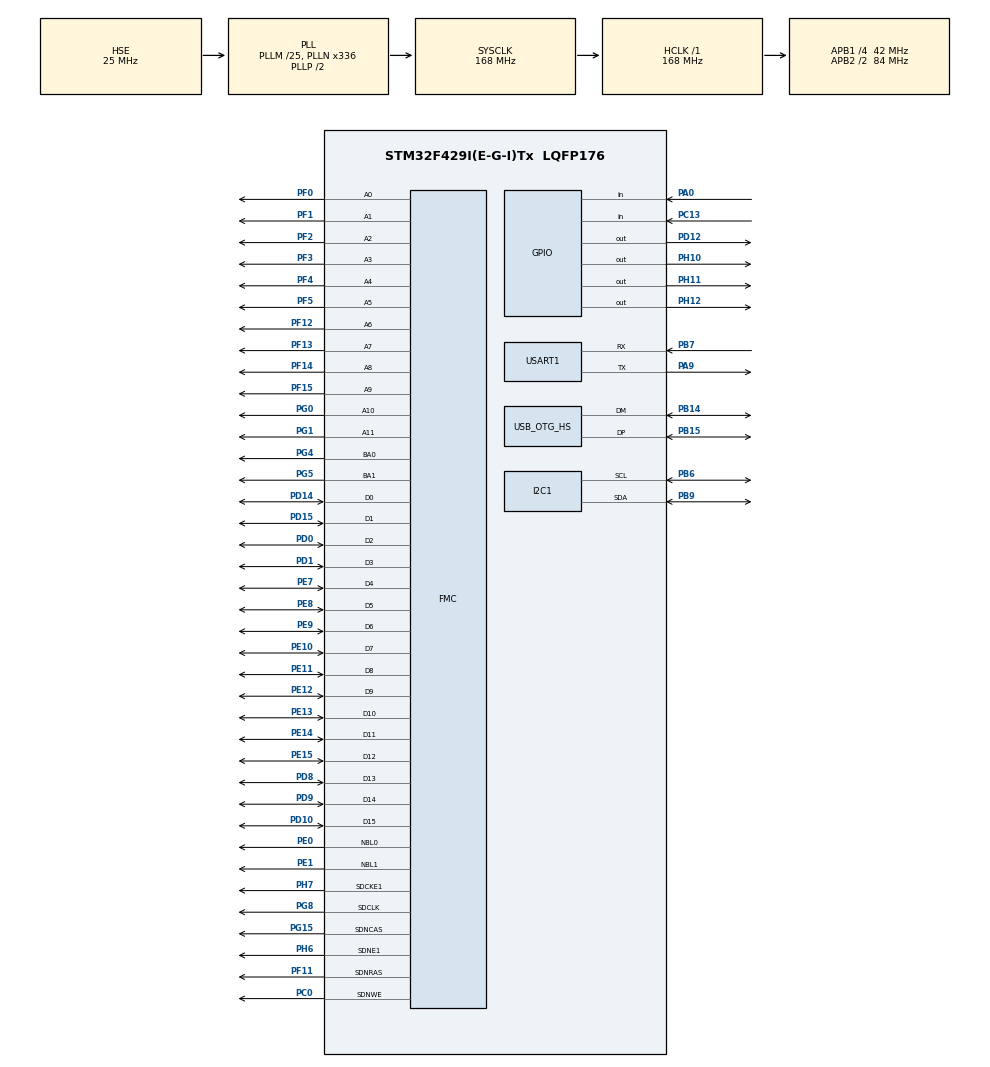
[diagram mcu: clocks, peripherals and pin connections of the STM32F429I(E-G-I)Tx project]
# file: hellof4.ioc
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Dma.I2C1_RX.1.Direction=DMA_PERIPH_TO_MEMORY
Dma.I2C1_RX.1.FIFOMode=DMA_FIFOMODE_DISABLE
Dma.I2C1_RX.1.Instance=DMA1_Stream0
Dma.I2C1_RX.1.MemDataAlignment=DMA_MDATAALIGN_BYTE
Dma.I2C1_RX.1.MemInc=DMA_MINC_ENABLE
Dma.I2C1_RX.1.Mode=DMA_NORMAL
Dma.I2C1_RX.1.PeriphDataAlignment=DMA_PDATAALIGN_BYTE
Dma.I2C1_RX.1.PeriphInc=DMA_PINC_DISABLE
Dma.I2C1_RX.1.Priority=DMA_PRIORITY_HIGH
Dma.I2C1_TX.2.Direction=DMA_MEMORY_TO_PERIPH
Dma.I2C1_TX.2.FIFOMode=DMA_FIFOMODE_DISABLE
Dma.I2C1_TX.2.Instance=DMA1_Stream6
Dma.I2C1_TX.2.MemDataAlignment=DMA_MDATAALIGN_BYTE
Dma.I2C1_TX.2.MemInc=DMA_MINC_ENABLE
Dma.I2C1_TX.2.Mode=DMA_NORMAL
Dma.I2C1_TX.2.PeriphDataAlignment=DMA_PDATAALIGN_BYTE
Dma.I2C1_TX.2.PeriphInc=DMA_PINC_DISABLE
Dma.I2C1_TX.2.Priority=DMA_PRIORITY_HIGH
Dma.Request0=USART1_TX
Dma.Request1=I2C1_RX
Dma.Request2=I2C1_TX
Dma.USART1_TX.0.Direction=DMA_MEMORY_TO_PERIPH
Dma.USART1_TX.0.FIFOMode=DMA_FIFOMODE_DISABLE
Dma.USART1_TX.0.Instance=DMA2_Stream7
Dma.USART1_TX.0.MemDataAlignment=DMA_MDATAALIGN_BYTE
Dma.USART1_TX.0.MemInc=DMA_MINC_ENABLE
Dma.USART1_TX.0.Mode=DMA_NORMAL
Dma.USART1_TX.0.PeriphDataAlignment=DMA_PDATAALIGN_BYTE
Dma.USART1_TX.0.PeriphInc=DMA_PINC_DISABLE
Dma.USART1_TX.0.Priority=DMA_PRIORITY_HIGH
FATFS._CODE_PAGE=936
FATFS._USE_LFN=1
FMC.CASLatency1=FMC_SDRAM_CAS_LATENCY_2
FMC.ExitSelfRefreshDelay1=7
FMC.LoadToActiveDelay1=2
FMC.RCDDelay1=2
FMC.RPDelay1=2
FMC.ReadBurst1=FMC_SDRAM_RBURST_ENABLE
FMC.RowCycleDelay1=7
FMC.SDClockPeriod1=FMC_SDRAM_CLOCK_PERIOD_2
FMC.SelfRefreshTime1=4
FMC.WriteRecoveryTime1=3
Mcu.Family=STM32F4
Mcu.Name=STM32F429I(E-G-I)Tx
Mcu.Package=LQFP176
NVIC.DMA1_Stream0_IRQn=true\:0\:0\:false\:false\:true
NVIC.DMA1_Stream6_IRQn=true\:0\:0\:false\:false\:true
NVIC.DMA2_Stream7_IRQn=true\:0\:0\:false\:false\:true
NVIC.OTG_HS_IRQn=true\:0\:0\:false\:false\:true
NVIC.PriorityGroup=NVIC_PRIORITYGROUP_4
PA0/WKUP.Signal=GPIO_Input
PA13.Mode=Serial_Wire
PA13.Signal=SYS_JTMS-SWDIO
PA14.Mode=Serial_Wire
PA14.Signal=SYS_JTCK-SWCLK
PA9.Mode=Asynchronous
PA9.Signal=USART1_TX
PB14.Mode=Host_FS
PB14.Signal=USB_OTG_HS_DM
PB15.Mode=Host_FS
PB15.Signal=USB_OTG_HS_DP
PB6.Mode=I2C
PB6.Signal=I2C1_SCL
PB7.Mode=Asynchronous
PB7.Signal=USART1_RX
PB9.Mode=I2C
PB9.Signal=I2C1_SDA
PC0.Signal=FMC_SDNWE
PC13.Signal=GPIO_Input
PC14/OSC32_IN.Mode=LSE-External-Oscillator
PC14/OSC32_IN.Signal=RCC_OSC32_IN
PC15/OSC32_OUT.Mode=LSE-External-Oscillator
PC15/OSC32_OUT.Signal=RCC_OSC32_OUT
PD0.Signal=FMC_D2_DA2
PD1.Signal=FMC_D3_DA3
PD10.Signal=FMC_D15_DA15
PD12.Signal=GPIO_Output
PD14.Signal=FMC_D0_DA0
PD15.Signal=FMC_D1_DA1
PD8.Signal=FMC_D13_DA13
PD9.Signal=FMC_D14_DA14
PE0.Signal=FMC_NBL0
PE1.Signal=FMC_NBL1
PE10.Signal=FMC_D7_DA7
PE11.Signal=FMC_D8_DA8
PE12.Signal=FMC_D9_DA9
PE13.Signal=FMC_D10_DA10
PE14.Signal=FMC_D11_DA11
PE15.Signal=FMC_D12_DA12
PE7.Signal=FMC_D4_DA4
PE8.Signal=FMC_D5_DA5
PE9.Signal=FMC_D6_DA6
PF0.Signal=FMC_A0
PF1.Signal=FMC_A1
PF11.Signal=FMC_SDNRAS
PF12.Signal=FMC_A6
PF13.Signal=FMC_A7
PF14.Signal=FMC_A8
PF15.Signal=FMC_A9
PF2.Signal=FMC_A2
PF3.Signal=FMC_A3
PF4.Signal=FMC_A4
PF5.Signal=FMC_A5
PG0.Signal=FMC_A10
PG1.Signal=FMC_A11
PG15.Signal=FMC_SDNCAS
PG4.Signal=FMC_A14_BA0
PG5.Signal=FMC_A15_BA1
PG8.Signal=FMC_SDCLK
PH0/OSC_IN.Mode=HSE-External-Oscillator
PH0/OSC_IN.Signal=RCC_OSC_IN
PH1/OSC_OUT.Mode=HSE-External-Oscillator
PH1/OSC_OUT.Signal=RCC_OSC_OUT
PH10.Signal=GPIO_Output
PH11.Signal=GPIO_Output
PH12.Signal=GPIO_Output
PH6.Mode=SdramChipSelect2_1
PH6.Signal=FMC_SDNE1
PH7.Mode=SdramChipSelect2_1
PH7.Signal=FMC_SDCKE1
ProjectManager.HeapSize=0x200
ProjectManager.StackSize=0x800
ProjectManager.TargetToolchain=MDK-ARM V5
RCC.48MHZClocksFreq_Value=48000000
RCC.AHBFreq_Value=168000000
RCC.APB1CLKDivider=RCC_HCLK_DIV4
RCC.APB1Freq_Value=42000000
RCC.APB1TimFreq_Value=84000000
RCC.APB2CLKDivider=RCC_HCLK_DIV2
RCC.APB2Freq_Value=84000000
RCC.APB2TimFreq_Value=168000000
RCC.CortexFreq_Value=168000000
RCC.HCLKFreq_Value=168000000
RCC.HSE_VALUE=25000000
RCC.HSI_VALUE=16000000
RCC.PLLM=25
RCC.PLLN=336
RCC.PLLQ=7
RCC.RCC_RTC_Clock_Source=RCC_RTCCLKSOURCE_LSE
RCC.RCC_RTC_Clock_SourceVirtual=RCC_RTCCLKSOURCE_LSE
RCC.SYSCLKFreq_VALUE=168000000
RCC.SYSCLKSource=RCC_SYSCLKSOURCE_PLLCLK
RCC.VCOOutputFreq_Value=336000000
SH.FMC_A0.0=FMC_A0,12b-sda1
SH.FMC_A1.0=FMC_A1,12b-sda1
SH.FMC_A10.0=FMC_A10,12b-sda1
SH.FMC_A11.0=FMC_A11,12b-sda1
SH.FMC_A14_BA0.0=FMC_BA0,FourSdramBanks1
SH.FMC_A15_BA1.0=FMC_BA1,FourSdramBanks1
SH.FMC_A2.0=FMC_A2,12b-sda1
SH.FMC_A3.0=FMC_A3,12b-sda1
SH.FMC_A4.0=FMC_A4,12b-sda1
SH.FMC_A5.0=FMC_A5,12b-sda1
SH.FMC_A6.0=FMC_A6,12b-sda1
SH.FMC_A7.0=FMC_A7,12b-sda1
SH.FMC_A8.0=FMC_A8,12b-sda1
SH.FMC_A9.0=FMC_A9,12b-sda1
SH.FMC_D0_DA0.0=FMC_D0,sd-16b-d1
SH.FMC_D10_DA10.0=FMC_D10,sd-16b-d1
SH.FMC_D11_DA11.0=FMC_D11,sd-16b-d1
SH.FMC_D12_DA12.0=FMC_D12,sd-16b-d1
SH.FMC_D13_DA13.0=FMC_D13,sd-16b-d1
SH.FMC_D14_DA14.0=FMC_D14,sd-16b-d1
SH.FMC_D15_DA15.0=FMC_D15,sd-16b-d1
SH.FMC_D1_DA1.0=FMC_D1,sd-16b-d1
SH.FMC_D2_DA2.0=FMC_D2,sd-16b-d1
SH.FMC_D3_DA3.0=FMC_D3,sd-16b-d1
SH.FMC_D4_DA4.0=FMC_D4,sd-16b-d1
SH.FMC_D5_DA5.0=FMC_D5,sd-16b-d1
SH.FMC_D6_DA6.0=FMC_D6,sd-16b-d1
SH.FMC_D7_DA7.0=FMC_D7,sd-16b-d1
SH.FMC_D8_DA8.0=FMC_D8,sd-16b-d1
SH.FMC_D9_DA9.0=FMC_D9,sd-16b-d1
SH.FMC_NBL0.0=FMC_NBL0,Sd2ByteEnable1
SH.FMC_NBL1.0=FMC_NBL1,Sd2ByteEnable1
SH.FMC_SDCLK.0=FMC_SDCLK,12b-sda1
SH.FMC_SDNCAS.0=FMC_SDNCAS,12b-sda1
SH.FMC_SDNRAS.0=FMC_SDNRAS,12b-sda1
SH.FMC_SDNWE.0=FMC_SDNWE,12b-sda1
USART1.VirtualMode=VM_ASYNC
USB_HOST.USBH_HandleTypeDef-ALL_Classes_HS=hUsbHostHS
USB_HOST.VirtualModeHS=All_Classes
USB_OTG_HS.VirtualMode-Host_FS=Host_FS
VP_FATFS_VS_USB.Mode=USB
VP_RNG_VS_RNG.Mode=RNG_Activate
VP_USB_HOST_VS_USB_HOST_ALL_CLASS_HS.Mode=ALL_Classes_HS
board=hellof4

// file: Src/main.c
/**
  ******************************************************************************
  * File Name          : main.c
  * Description        : Main program body
  ******************************************************************************
  *
  * Copyright (c) 2019 STMicroelectronics International N.V.
  * All rights reserved.
  *
  * Redistribution and use in source and binary forms, with or without
  * modification, are permitted, provided that the following conditions are met:
  *
  * 1. Redistribution of source code must retain the above copyright notice,
  *    this list of conditions and the following disclaimer.
  * 2. Redistributions in binary form must reproduce the above copyright notice,
  *    this list of conditions and the following disclaimer in the documentation
  *    and/or other materials provided with the distribution.
  * 3. Neither the name of STMicroelectronics nor the names of other
  *    contributors to this software may be used to endorse or promote products
  *    derived from this software without specific written permission.
  * 4. This software, including modifications and/or derivative works of this
  *    software, must execute solely and exclusively on microcontroller or
  *    microprocessor devices manufactured by or for STMicroelectronics.
  * 5. Redistribution and use of this software other than as permitted under
  *    this license is void and will automatically terminate your rights under
  *    this license.
  *
  * THIS SOFTWARE IS PROVIDED BY STMICROELECTRONICS AND CONTRIBUTORS "AS IS"
  * AND ANY EXPRESS, IMPLIED OR STATUTORY WARRANTIES, INCLUDING, BUT NOT
  * LIMITED TO, THE IMPLIED WARRANTIES OF MERCHANTABILITY, FITNESS FOR A
  * PARTICULAR PURPOSE AND NON-INFRINGEMENT OF THIRD PARTY INTELLECTUAL PROPERTY
  * RIGHTS ARE DISCLAIMED TO THE FULLEST EXTENT PERMITTED BY LAW. IN NO EVENT
  * SHALL STMICROELECTRONICS OR CONTRIBUTORS BE LIABLE FOR ANY DIRECT, INDIRECT,
  * INCIDENTAL, SPECIAL, EXEMPLARY, OR CONSEQUENTIAL DAMAGES (INCLUDING, BUT NOT
  * LIMITED TO, PROCUREMENT OF SUBSTITUTE GOODS OR SERVICES; LOSS OF USE, DATA,
  * OR PROFITS; OR BUSINESS INTERRUPTION) HOWEVER CAUSED AND ON ANY THEORY OF
  * LIABILITY, WHETHER IN CONTRACT, STRICT LIABILITY, OR TORT (INCLUDING
  * NEGLIGENCE OR OTHERWISE) ARISING IN ANY WAY OUT OF THE USE OF THIS SOFTWARE,
  * EVEN IF ADVISED OF THE POSSIBILITY OF SUCH DAMAGE.
  *
  ******************************************************************************
  */
#include "main.h"
#include "stm32f4xx_hal.h"
#include "dma.h"
#include "fatfs.h"
#include "i2c.h"
#include "rng.h"
#include "usart.h"
#include "usb_host.h"
#include "gpio.h"
#include "fmc.h"

/* USER CODE BEGIN Includes */
#include "user_main.h"

/* USER CODE END Includes */

/* USER CODE BEGIN PV */
/* Private variables ---------------------------------------------------------*/

/* USER CODE END PV */

void SystemClock_Config(void);
void Error_Handler(void);
void MX_USB_HOST_Process(void);

/* USER CODE BEGIN PFP */
/* Private function prototypes -----------------------------------------------*/

/* USER CODE END PFP */

int main(void)
{

  /* USER CODE BEGIN 1 */
  user_system_setup();
  /* USER CODE END 1 */

  /* MCU Configuration----------------------------------------------------------*/

  /* Reset of all peripherals, Initializes the Flash interface and the Systick. */
  HAL_Init();

  /* Configure the system clock */
  SystemClock_Config();

  /* Initialize all configured peripherals */
  MX_GPIO_Init();
  MX_DMA_Init();
  MX_FMC_Init();
  MX_RNG_Init();
  MX_USART1_UART_Init();
  MX_I2C1_Init();
  MX_USB_HOST_Init();
  MX_FATFS_Init();

  /* USER CODE BEGIN 2 */
  user_setup();

  /* USER CODE END 2 */

  /* Infinite loop */
  while (1)
  {
    MX_USB_HOST_Process();

  /* USER CODE BEGIN 3 */
    user_loop();

  }
  /* USER CODE END 3 */

}

/** System Clock Configuration
*/
void SystemClock_Config(void)
{

  RCC_OscInitTypeDef RCC_OscInitStruct;
  RCC_ClkInitTypeDef RCC_ClkInitStruct;

    /**Configure the main internal regulator output voltage
    */
  __HAL_RCC_PWR_CLK_ENABLE();

  __HAL_PWR_VOLTAGESCALING_CONFIG(PWR_REGULATOR_VOLTAGE_SCALE1);

    /**Initializes the CPU, AHB and APB busses clocks
    */
  RCC_OscInitStruct.OscillatorType = RCC_OSCILLATORTYPE_HSE;
  RCC_OscInitStruct.HSEState = RCC_HSE_ON;
  RCC_OscInitStruct.PLL.PLLState = RCC_PLL_ON;
  RCC_OscInitStruct.PLL.PLLSource = RCC_PLLSOURCE_HSE;
  RCC_OscInitStruct.PLL.PLLM = 25;
  RCC_OscInitStruct.PLL.PLLN = 336;
  RCC_OscInitStruct.PLL.PLLP = RCC_PLLP_DIV2;
  RCC_OscInitStruct.PLL.PLLQ = 7;
  if (HAL_RCC_OscConfig(&RCC_OscInitStruct) != HAL_OK)
  {
    Error_Handler();
  }

    /**Initializes the CPU, AHB and APB busses clocks
    */
  RCC_ClkInitStruct.ClockType = RCC_CLOCKTYPE_HCLK|RCC_CLOCKTYPE_SYSCLK
                              |RCC_CLOCKTYPE_PCLK1|RCC_CLOCKTYPE_PCLK2;
  RCC_ClkInitStruct.SYSCLKSource = RCC_SYSCLKSOURCE_PLLCLK;
  RCC_ClkInitStruct.AHBCLKDivider = RCC_SYSCLK_DIV1;
  RCC_ClkInitStruct.APB1CLKDivider = RCC_HCLK_DIV4;
  RCC_ClkInitStruct.APB2CLKDivider = RCC_HCLK_DIV2;

  if (HAL_RCC_ClockConfig(&RCC_ClkInitStruct, FLASH_LATENCY_5) != HAL_OK)
  {
    Error_Handler();
  }

    /**Configure the Systick interrupt time
    */
  HAL_SYSTICK_Config(HAL_RCC_GetHCLKFreq()/1000);

    /**Configure the Systick
    */
  HAL_SYSTICK_CLKSourceConfig(SYSTICK_CLKSOURCE_HCLK);

  /* SysTick_IRQn interrupt configuration */
  HAL_NVIC_SetPriority(SysTick_IRQn, 0, 0);
}

void Error_Handler(void)
{
  while(1)
  {
  }
}

/************************ (C) COPYRIGHT STMicroelectronics *****END OF FILE****/
